# apollo1 register map
Vendor: Ambiq Micro; Series: Apollo; File version: 1.0
CPU: CM4 r1p0, little endian, MPU, FPU, 3 interrupt priority bits
Registers are 32-bit, read-write, reset 0x0 unless marked. A register's access mark holds for its fields unless they carry their own. Offsets are from the block's base; [hi:lo] are bit positions; {n}, {i} and the like mark numbered series.

## MCUCTRL — MCU Miscellaneous Control Logic
Base 0x40020000
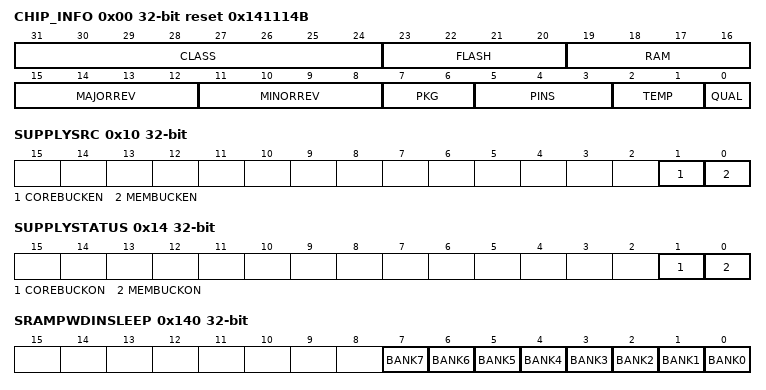
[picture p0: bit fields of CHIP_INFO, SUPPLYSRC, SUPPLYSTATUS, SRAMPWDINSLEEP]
0x00 CHIP_INFO reset 0x141114B — Chip Information Register
  [31:24] CLASS — Device class.
    1=APOLLO (APOLLO value.)
  [23:20] FLASH — Device flash size.
    3=256K (256K of available flash. value.); 4=512K (512K of available flash. value.)
  [19:16] RAM — Device RAM size.
    0=32K (32K of available SRAM. value.); 1=64K (64K of available SRAM. value.)
  [15:12] MAJORREV — Major device revision number.
  [11:8] MINORREV — Minor device revision number.
  [7:6] PKG — Device package type.
    2=BGA (Ball grid array. value.); 3=CSP (Chip-scale package. value.)
  [5:3] PINS — Number of pins.
    1=41PINS (41 package pins total. value.)
  [2:1] TEMP — Device temperature range.
    0=COMMERCIAL (Commercial temperature range. value.)
  [0] QUAL — Device qualified.
    0=PROTOTYPE (Prototype device. value.); 1=QUALIFIED (Fully qualified device. value.)
0x04 CHIPID0 — Unique Chip ID 0
  [31:0] VALUE — Unique chip ID 0.
    0=APOLLO (Apollo CHIPID0. value.)
0x08 CHIPID1 — Unique Chip ID 1
  [31:0] VALUE — Unique chip ID 1.
    0=APOLLO (Apollo CHIPID1. value.)
0x0C CHIPREV — Chip Revision
  [7:0] REVISION — Chip Revision Number.
    0=APOLLO (Apollo CHIPREV. value.)
0x10 SUPPLYSRC — Memory and Core Voltage Supply Source Select Register
  [1] COREBUCKEN — Enables and Selects the Core Buck as the supply for the low-voltage power domain.
    1=EN (Enable the Core Buck for the low-voltage power domain. value.)
  [0] MEMBUCKEN — Enables and select the Memory Buck as the supply for the Flash and SRAM power domain.
    1=EN (Enable the Memory Buck as the supply for flash and SRAM. value.)
0x14 SUPPLYSTATUS — Memory and Core Voltage Supply Source Status Register
  [1] COREBUCKON — Indicates whether the Core low-voltage domain is supplied from the LDO or the Buck.
    0=LDO (Indicates the the LDO is supplying the Core low-voltage. value.); 1=BUCK (Indicates the the Buck is supplying the Core low-voltage. value.)
  [0] MEMBUCKON — Indicate whether the Memory power domain is supplied from the LDO or the Buck.
    0=LDO (Indicates the LDO is supplying the memory power domain. value.); 1=BUCK (Indicates the Buck is supplying the memory power domain. value.)
0xFC BANDGAPEN — Band Gap Enable
  [0] BGPEN — Bandgap Enable
    0=DIS (Bandgap disable. value.); 1=EN (Bandgap enable. value.)
0x140 SRAMPWDINSLEEP — Powerdown an SRAM Bank in Deep Sleep mode
  [n] BANK{n} (n=0..7) — Force SRAM Bank {n} to powerdown in deep sleep mode, causing the contents of the bank to be lost.
    0=NORMAL (SRAM Bank {n} normal operation. value.); 1=PWRDN_IN_DEEPSLEEP (SRAM Bank {n} deep sleep. value.)
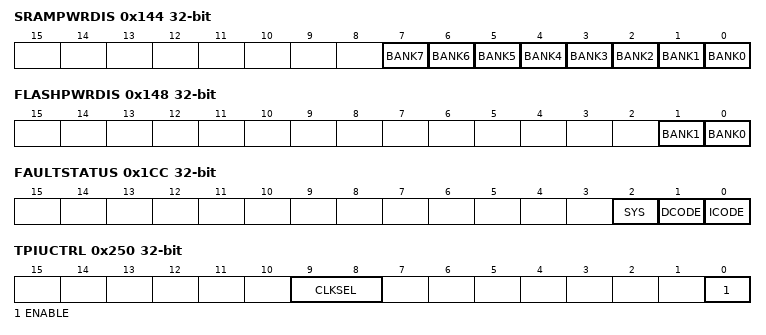
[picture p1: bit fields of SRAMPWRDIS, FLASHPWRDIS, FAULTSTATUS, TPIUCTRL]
0x144 SRAMPWRDIS — Disables individual banks of the SRAM array
  [n] BANK{n} (n=0..7) — Remove power from SRAM Bank {n} which will cause an access to its address space to generate a Hard Fault.
    1=DIS (Disable SRAM Bank {n}. value.)
0x148 FLASHPWRDIS — Disables individual banks of the Flash array
  [1] BANK1 — Remove power from Flash Bank 1 which will cause an access to its address space to generate a Hard Fault.
    1=DIS (Disable Flash instance 1. value.)
  [0] BANK0 — Remove power from Flash Bank 0 which will cause an access to its address space to generate a Hard Fault.
    1=DIS (Disable Flash instance 0. value.)
0x1C0 ICODEFAULTADDR — ICODE bus address which was present when a bus fault occurred.
  [31:0] ADDR — The ICODE bus address observed when a Bus Fault occurred. Once an address is captured in this field, it is held until the corresponding Fault Observed bit is cleared in the FAULTSTATUS register.
0x1C4 DCODEFAULTADDR — DCODE bus address which was present when a bus fault occurred.
  [31:0] ADDR — The DCODE bus address observed when a Bus Fault occurred. Once an address is captured in this field, it is held until the corresponding Fault Observed bit is cleared in the FAULTSTATUS register.
0x1C8 SYSFAULTADDR — System bus address which was present when a bus fault occurred.
  [31:0] ADDR — SYS bus address observed when a Bus Fault occurred. Once an address is captured in this field, it is held until the corresponding Fault Observed bit is cleared in the FAULTSTATUS register.
0x1CC FAULTSTATUS — Reflects the status of the bus decoders' fault detection. Any write to this register will clear all of the status bits within the register.
  [2] SYS — SYS Bus Decoder Fault Detected bit. When set, a fault has been detected, and the SYSFAULTADDR register will contain the bus address which generated the fault.
    0=NOFAULT (No bus fault has been detected. value.); 1=FAULT (Bus fault detected. value.)
  [1] DCODE — DCODE Bus Decoder Fault Detected bit. When set, a fault has been detected, and the DCODEFAULTADDR register will contain the bus address which generated the fault.
    0=NOFAULT (No DCODE fault has been detected. value.); 1=FAULT (DCODE fault detected. value.)
  [0] ICODE — The ICODE Bus Decoder Fault Detected bit. When set, a fault has been detected, and the ICODEFAULTADDR register will contain the bus address which generated the fault.
    0=NOFAULT (No ICODE fault has been detected. value.); 1=FAULT (ICODE fault detected. value.)
0x1D0 FAULTCAPTUREEN — Enable the fault capture registers
  [0] ENABLE — Fault Capture Enable field. When set, the Fault Capture monitors are enabled and addresses which generate a hard fault are captured into the FAULTADDR registers.
    0=DIS (Disable fault capture. value.); 1=EN (Enable fault capture. value.)
0x250 TPIUCTRL — TPIU Control Register. Determines the clock enable and frequency for the M4's TPIU interface.
  [9:8] CLKSEL — This field selects the frequency of the ARM M4 TPIU port.
    0=LOW_PWR (Low power state. value.); 1=6MHZ (Selects 6MHz frequency. value.); 2=3MHZ (Selects 3MHz frequency. value.); 3=1_5MHZ (Selects 1.5 MHz frequency. value.)
  [0] ENABLE — TPIU Enable field. When set, the ARM M4 TPIU is enabled and data can be streamed out of the MCU's SWO port using the ARM ITM and TPIU modules.
    0=DIS (Disable the TPIU. value.); 1=EN (Enable the TPIU. value.)
